# ior7f701057 register map
Registers are 8-bit, access not given, no defined reset value unless marked. A register's access mark holds for its fields unless they carry their own. Addresses are absolute; registers are grouped by the start of their names; [hi:lo] are bit positions; {n}, {i} and the like mark numbered series; 'fields as' and 'values as' point back to an identical list.

## SFR (part 3 of 3)
0xFFFF9002 ICCSIH3ICL_1
0xFFFF9003 ICTAUD0I2H
  [7] CTCSIH3IC_1 ro, [7] CTTAUD0I2 ro, [4] RFCSIH3IC_1, [4] RFTAUD0I2
0xFFFF9003 ICCSIH3ICH_1
0xFFFF9004 ICTAUD0I4 16-bit
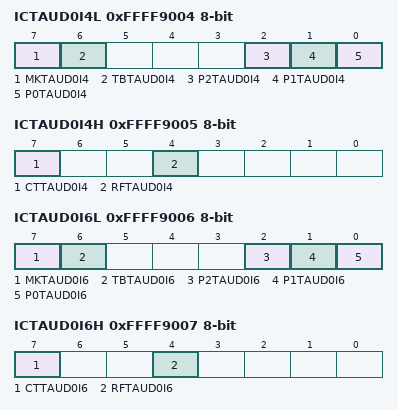
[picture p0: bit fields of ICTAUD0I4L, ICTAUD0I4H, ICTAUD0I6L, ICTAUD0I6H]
0xFFFF9004 ICTAUD0I4L
  [7] MKTAUD0I4, [6] TBTAUD0I4, [2] P2TAUD0I4, [1] P1TAUD0I4, [0] P0TAUD0I4
0xFFFF9005 ICTAUD0I4H
  [7] CTTAUD0I4 ro, [4] RFTAUD0I4
0xFFFF9006 ICTAUD0I6 16-bit
0xFFFF9006 ICTAUD0I6L
  [7] MKTAUD0I6, [6] TBTAUD0I6, [2] P2TAUD0I6, [1] P1TAUD0I6, [0] P0TAUD0I6
0xFFFF9007 ICTAUD0I6H
  [7] CTTAUD0I6 ro, [4] RFTAUD0I6
0xFFFF9008 ICTAUD0I8 16-bit
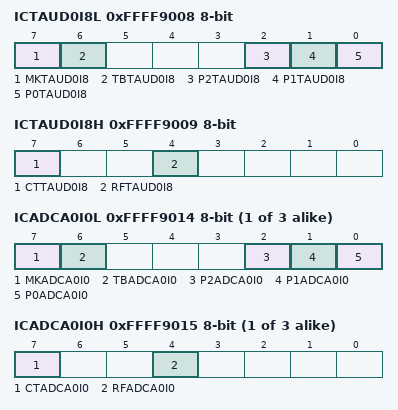
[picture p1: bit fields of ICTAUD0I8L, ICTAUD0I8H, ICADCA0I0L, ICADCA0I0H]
0xFFFF9008 ICTAUD0I8L
  [7] MKTAUD0I8, [6] TBTAUD0I8, [2] P2TAUD0I8, [1] P1TAUD0I8, [0] P0TAUD0I8
0xFFFF9009 ICTAUD0I8H
  [7] CTTAUD0I8 ro, [4] RFTAUD0I8
0xFFFF900A ICTAUD0I10 16-bit
0xFFFF900A ICTAUD0I10L
  [7] MKCSIH3IR_1, [7] MKTAUD0I10, [6] TBCSIH3IR_1, [6] TBTAUD0I10, [2] P2CSIH3IR_1, [2] P2TAUD0I10, [1] P1CSIH3IR_1, [1] P1TAUD0I10, [0] P0CSIH3IR_1, [0] P0TAUD0I10
0xFFFF900A ICCSIH3IR_1 16-bit
0xFFFF900A ICCSIH3IRL_1
0xFFFF900B ICTAUD0I10H
  [7] CTCSIH3IR_1 ro, [7] CTTAUD0I10 ro, [4] RFCSIH3IR_1, [4] RFTAUD0I10
0xFFFF900B ICCSIH3IRH_1
0xFFFF900C ICTAUD0I12 16-bit
0xFFFF900C ICTAUD0I12L
  [7] MKCSIH3IRE_1, [7] MKTAUD0I12, [6] TBCSIH3IRE_1, [6] TBTAUD0I12, [2] P2CSIH3IRE_1, [2] P2TAUD0I12, [1] P1CSIH3IRE_1, [1] P1TAUD0I12, [0] P0CSIH3IRE_1, [0] P0TAUD0I12
0xFFFF900C ICCSIH3IRE_1 16-bit
0xFFFF900C ICCSIH3IREL_1
0xFFFF900D ICTAUD0I12H
  [7] CTCSIH3IRE_1 ro, [7] CTTAUD0I12 ro, [4] RFCSIH3IRE_1, [4] RFTAUD0I12
0xFFFF900D ICCSIH3IREH_1
0xFFFF900E ICTAUD0I14 16-bit
0xFFFF900E ICTAUD0I14L
  [7] MKCSIH3IJC_1, [7] MKTAUD0I14, [6] TBCSIH3IJC_1, [6] TBTAUD0I14, [2] P2CSIH3IJC_1, [2] P2TAUD0I14, [1] P1CSIH3IJC_1, [1] P1TAUD0I14, [0] P0CSIH3IJC_1, [0] P0TAUD0I14
0xFFFF900E ICCSIH3IJC_1 16-bit
0xFFFF900E ICCSIH3IJCL_1
0xFFFF900F ICTAUD0I14H
  [7] CTCSIH3IJC_1 ro, [7] CTTAUD0I14 ro, [4] RFCSIH3IJC_1, [4] RFTAUD0I14
0xFFFF900F ICCSIH3IJCH_1
0xFFFF9010 ICTAPA0IPEK0 16-bit
0xFFFF9010 ICTAPA0IPEK0L
  [7] MKCSIH1IC_1, [7] MKTAPA0IPEK0, [6] TBCSIH1IC_1, [6] TBTAPA0IPEK0, [2] P2CSIH1IC_1, [2] P2TAPA0IPEK0, [1] P1CSIH1IC_1, [1] P1TAPA0IPEK0, [0] P0CSIH1IC_1, [0] P0TAPA0IPEK0
0xFFFF9010 ICCSIH1IC_1 16-bit
0xFFFF9010 ICCSIH1ICL_1
0xFFFF9011 ICTAPA0IPEK0H
  [7] CTCSIH1IC_1 ro, [7] CTTAPA0IPEK0 ro, [4] RFCSIH1IC_1, [4] RFTAPA0IPEK0
0xFFFF9011 ICCSIH1ICH_1
0xFFFF9012 ICTAPA0IVLY0 16-bit
0xFFFF9012 ICTAPA0IVLY0L
  [7] MKCSIH1IR_1, [7] MKTAPA0IVLY0, [6] TBCSIH1IR_1, [6] TBTAPA0IVLY0, [2] P2CSIH1IR_1, [2] P2TAPA0IVLY0, [1] P1CSIH1IR_1, [1] P1TAPA0IVLY0, [0] P0CSIH1IR_1, [0] P0TAPA0IVLY0
0xFFFF9012 ICCSIH1IR_1 16-bit
0xFFFF9012 ICCSIH1IRL_1
0xFFFF9013 ICTAPA0IVLY0H
  [7] CTCSIH1IR_1 ro, [7] CTTAPA0IVLY0 ro, [4] RFCSIH1IR_1, [4] RFTAPA0IVLY0
0xFFFF9013 ICCSIH1IRH_1
{0xFFFF9014+2i} ICADCA0I{i} 16-bit (i=0..2)
{0xFFFF9014+2i} ICADCA0I{i}L (i=0..2)
  [7] MKADCA0I{i}, [6] TBADCA0I{i}, [2] P2ADCA0I{i}, [1] P1ADCA0I{i}, [0] P0ADCA0I{i}
{0xFFFF9015+2i} ICADCA0I{i}H (i=0..2)
  [7] CTADCA0I{i} ro, [4] RFADCA0I{i}
0xFFFF901A ICDCUTDI 16-bit
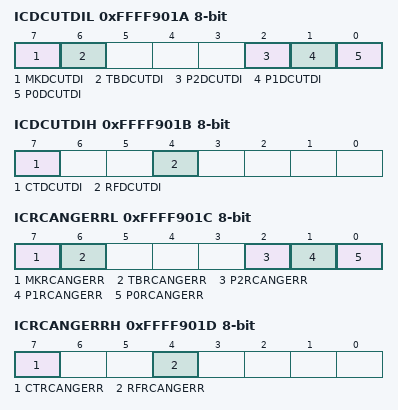
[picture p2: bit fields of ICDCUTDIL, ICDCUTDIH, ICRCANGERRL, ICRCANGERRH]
0xFFFF901A ICDCUTDIL
  [7] MKDCUTDI, [6] TBDCUTDI, [2] P2DCUTDI, [1] P1DCUTDI, [0] P0DCUTDI
0xFFFF901B ICDCUTDIH
  [7] CTDCUTDI ro, [4] RFDCUTDI
0xFFFF901C ICRCANGERR 16-bit
0xFFFF901C ICRCANGERRL
  [7] MKRCANGERR, [6] TBRCANGERR, [2] P2RCANGERR, [1] P1RCANGERR, [0] P0RCANGERR
0xFFFF901D ICRCANGERRH
  [7] CTRCANGERR ro, [4] RFRCANGERR
0xFFFF901E ICRCANGRECC 16-bit
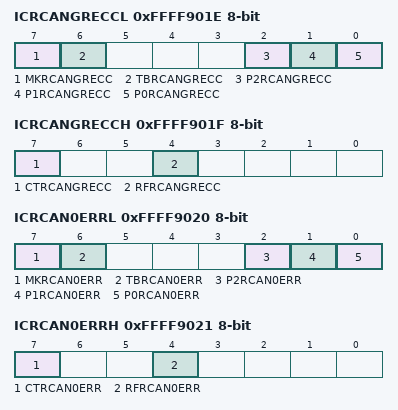
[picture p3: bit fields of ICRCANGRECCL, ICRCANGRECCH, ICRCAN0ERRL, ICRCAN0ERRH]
0xFFFF901E ICRCANGRECCL
  [7] MKRCANGRECC, [6] TBRCANGRECC, [2] P2RCANGRECC, [1] P1RCANGRECC, [0] P0RCANGRECC
0xFFFF901F ICRCANGRECCH
  [7] CTRCANGRECC ro, [4] RFRCANGRECC
0xFFFF9020 ICRCAN0ERR 16-bit
0xFFFF9020 ICRCAN0ERRL
  [7] MKRCAN0ERR, [6] TBRCAN0ERR, [2] P2RCAN0ERR, [1] P1RCAN0ERR, [0] P0RCAN0ERR
0xFFFF9021 ICRCAN0ERRH
  [7] CTRCAN0ERR ro, [4] RFRCAN0ERR
0xFFFF9022 ICRCAN0REC 16-bit
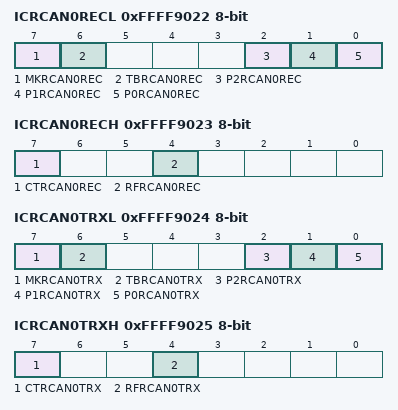
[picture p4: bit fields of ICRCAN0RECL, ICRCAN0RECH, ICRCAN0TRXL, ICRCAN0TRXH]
0xFFFF9022 ICRCAN0RECL
  [7] MKRCAN0REC, [6] TBRCAN0REC, [2] P2RCAN0REC, [1] P1RCAN0REC, [0] P0RCAN0REC
0xFFFF9023 ICRCAN0RECH
  [7] CTRCAN0REC ro, [4] RFRCAN0REC
0xFFFF9024 ICRCAN0TRX 16-bit
0xFFFF9024 ICRCAN0TRXL
  [7] MKRCAN0TRX, [6] TBRCAN0TRX, [2] P2RCAN0TRX, [1] P1RCAN0TRX, [0] P0RCAN0TRX
0xFFFF9025 ICRCAN0TRXH
  [7] CTRCAN0TRX ro, [4] RFRCAN0TRX
0xFFFF9026 ICCSIG0IC 16-bit
0xFFFF9026 ICCSIG0ICL
0xFFFF9026 ICCSIH1IRE_1 16-bit
0xFFFF9026 ICCSIH1IREL_1
  [7] MKCSIG0IC, [7] MKCSIH1IRE_1, [6] TBCSIG0IC, [6] TBCSIH1IRE_1, [2] P2CSIG0IC, [2] P2CSIH1IRE_1, [1] P1CSIG0IC, [1] P1CSIH1IRE_1, [0] P0CSIG0IC, [0] P0CSIH1IRE_1
0xFFFF9027 ICCSIG0ICH
0xFFFF9027 ICCSIH1IREH_1
  [7] CTCSIG0IC ro, [7] CTCSIH1IRE_1 ro, [4] RFCSIG0IC, [4] RFCSIH1IRE_1
0xFFFF9028 ICCSIG0IR 16-bit
0xFFFF9028 ICCSIG0IRL
0xFFFF9028 ICCSIH1IJC_1 16-bit
0xFFFF9028 ICCSIH1IJCL_1
  [7] MKCSIG0IR, [7] MKCSIH1IJC_1, [6] TBCSIG0IR, [6] TBCSIH1IJC_1, [2] P2CSIG0IR, [2] P2CSIH1IJC_1, [1] P1CSIG0IR, [1] P1CSIH1IJC_1, [0] P0CSIG0IR, [0] P0CSIH1IJC_1
0xFFFF9029 ICCSIG0IRH
0xFFFF9029 ICCSIH1IJCH_1
  [7] CTCSIG0IR ro, [7] CTCSIH1IJC_1 ro, [4] RFCSIG0IR, [4] RFCSIH1IJC_1
0xFFFF902A ICCSIH0IC 16-bit
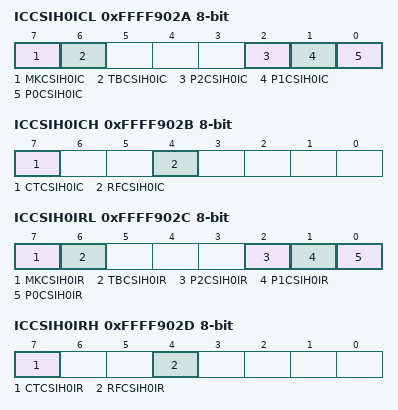
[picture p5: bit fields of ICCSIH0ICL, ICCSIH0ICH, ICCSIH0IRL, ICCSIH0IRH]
0xFFFF902A ICCSIH0ICL
  [7] MKCSIH0IC, [6] TBCSIH0IC, [2] P2CSIH0IC, [1] P1CSIH0IC, [0] P0CSIH0IC
0xFFFF902B ICCSIH0ICH
  [7] CTCSIH0IC ro, [4] RFCSIH0IC
0xFFFF902C ICCSIH0IR 16-bit
0xFFFF902C ICCSIH0IRL
  [7] MKCSIH0IR, [6] TBCSIH0IR, [2] P2CSIH0IR, [1] P1CSIH0IR, [0] P0CSIH0IR
0xFFFF902D ICCSIH0IRH
  [7] CTCSIH0IR ro, [4] RFCSIH0IR
0xFFFF902E ICCSIH0IRE 16-bit
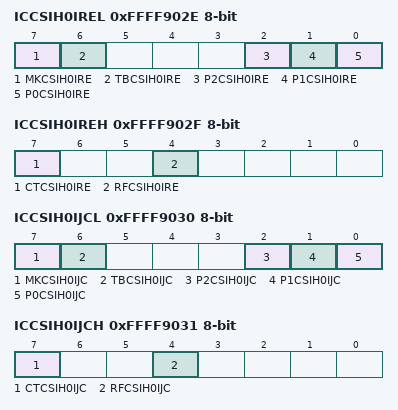
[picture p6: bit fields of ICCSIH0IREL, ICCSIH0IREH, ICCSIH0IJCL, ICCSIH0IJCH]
0xFFFF902E ICCSIH0IREL
  [7] MKCSIH0IRE, [6] TBCSIH0IRE, [2] P2CSIH0IRE, [1] P1CSIH0IRE, [0] P0CSIH0IRE
0xFFFF902F ICCSIH0IREH
  [7] CTCSIH0IRE ro, [4] RFCSIH0IRE
0xFFFF9030 ICCSIH0IJC 16-bit
0xFFFF9030 ICCSIH0IJCL
  [7] MKCSIH0IJC, [6] TBCSIH0IJC, [2] P2CSIH0IJC, [1] P1CSIH0IJC, [0] P0CSIH0IJC
0xFFFF9031 ICCSIH0IJCH
  [7] CTCSIH0IJC ro, [4] RFCSIH0IJC
0xFFFF9032 ICRLIN30 16-bit
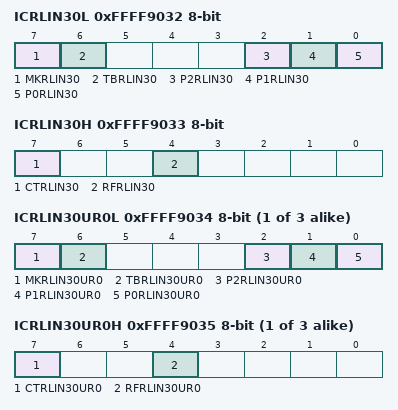
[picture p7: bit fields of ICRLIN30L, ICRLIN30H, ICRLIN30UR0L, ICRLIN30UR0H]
0xFFFF9032 ICRLIN30L
  [7] MKRLIN30, [6] TBRLIN30, [2] P2RLIN30, [1] P1RLIN30, [0] P0RLIN30
0xFFFF9033 ICRLIN30H
  [7] CTRLIN30 ro, [4] RFRLIN30
{0xFFFF9034+2i} ICRLIN30UR{i} 16-bit (i=0..2)
{0xFFFF9034+2i} ICRLIN30UR{i}L (i=0..2)
  [7] MKRLIN30UR{i}, [6] TBRLIN30UR{i}, [2] P2RLIN30UR{i}, [1] P1RLIN30UR{i}, [0] P0RLIN30UR{i}
{0xFFFF9035+2i} ICRLIN30UR{i}H (i=0..2)
  [7] CTRLIN30UR{i} ro, [4] RFRLIN30UR{i}
{0xFFFF903A+2i} ICP{i} 16-bit (i=0..2)
0xFFFF903A ICP0L
  [7] MKCSIH2IR_1, [7] MKP0, [6] TBCSIH2IR_1, [6] TBP0, [2] P2CSIH2IR_1, [2] P2P0, [1] P1CSIH2IR_1, [1] P1P0, [0] P0CSIH2IR_1, [0] P0P0
0xFFFF903A ICCSIH2IR_1 16-bit
0xFFFF903A ICCSIH2IRL_1
0xFFFF903B ICP0H
  [7] CTCSIH2IR_1 ro, [7] CTP0 ro, [4] RFCSIH2IR_1, [4] RFP0
0xFFFF903B ICCSIH2IRH_1
0xFFFF903C ICP1L
  [7] MKCSIH2IRE_1, [7] MKP1, [6] TBCSIH2IRE_1, [6] TBP1, [2] P2CSIH2IRE_1, [2] P2P1, [1] P1CSIH2IRE_1, [1] P1P1, [0] P0CSIH2IRE_1, [0] P0P1
0xFFFF903C ICCSIH2IRE_1 16-bit
0xFFFF903C ICCSIH2IREL_1
0xFFFF903D ICP1H
  [7] CTCSIH2IRE_1 ro, [7] CTP1 ro, [4] RFCSIH2IRE_1, [4] RFP1
0xFFFF903D ICCSIH2IREH_1
0xFFFF903E ICP2L
  [7] MKCSIH2IJC_1, [7] MKP2, [6] TBCSIH2IJC_1, [6] TBP2, [2] P2CSIH2IJC_1, [2] P2P2, [1] P1CSIH2IJC_1, [1] P1P2, [0] P0CSIH2IJC_1, [0] P0P2
0xFFFF903E ICCSIH2IJC_1 16-bit
0xFFFF903E ICCSIH2IJCL_1
0xFFFF903F ICP2H
  [7] CTCSIH2IJC_1 ro, [7] CTP2 ro, [4] RFCSIH2IJC_1, [4] RFP2
0xFFFF903F ICCSIH2IJCH_1
0xFFFF9078 FNC 16-bit ro
0xFFFF9079 FNCH ro
  [4] FNRF
0xFFFF907A FIC 16-bit ro
0xFFFF907B FICH ro
  [4] FIRF
0xFFFF90F0 IMR0 32-bit
0xFFFF90F0 IMR0L 16-bit
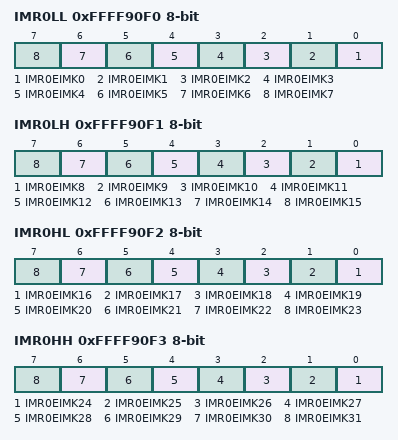
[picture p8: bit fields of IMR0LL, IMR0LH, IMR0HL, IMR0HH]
0xFFFF90F0 IMR0LL
  [n] IMR0EIMK{n} (n=0..7)
0xFFFF90F1 IMR0LH
  [n-8] IMR0EIMK{n} (n=8..15)
0xFFFF90F2 IMR0H 16-bit
0xFFFF90F2 IMR0HL
  [n-16] IMR0EIMK{n} (n=16..23)
0xFFFF90F3 IMR0HH
  [n-24] IMR0EIMK{n} (n=24..31)
0xFFFFA040 ICWDTA0 16-bit
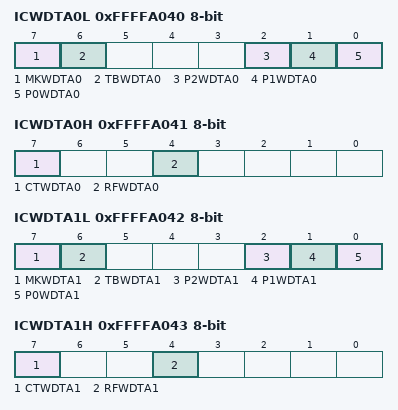
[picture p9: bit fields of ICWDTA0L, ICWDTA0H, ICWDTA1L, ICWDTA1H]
0xFFFFA040 ICWDTA0L
  [7] MKWDTA0, [6] TBWDTA0, [2] P2WDTA0, [1] P1WDTA0, [0] P0WDTA0
0xFFFFA041 ICWDTA0H
  [7] CTWDTA0 ro, [4] RFWDTA0
0xFFFFA042 ICWDTA1 16-bit
0xFFFFA042 ICWDTA1L
  [7] MKWDTA1, [6] TBWDTA1, [2] P2WDTA1, [1] P1WDTA1, [0] P0WDTA1
0xFFFFA043 ICWDTA1H
  [7] CTWDTA1 ro, [4] RFWDTA1
{0xFFFFA03E+2i} ICP{i} 16-bit (i=3..5)
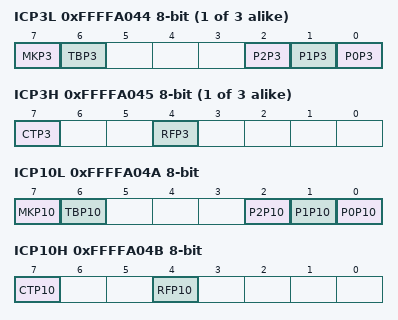
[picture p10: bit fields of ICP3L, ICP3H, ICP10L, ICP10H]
{0xFFFFA03E+2i} ICP{i}L (i=3..5)
  [7] MKP{i}, [6] TBP{i}, [2] P2P{i}, [1] P1P{i}, [0] P0P{i}
{0xFFFFA03F+2i} ICP{i}H (i=3..5)
  [7] CTP{i} ro, [4] RFP{i}
0xFFFFA04A ICP10 16-bit
0xFFFFA04A ICP10L
  [7] MKP10, [6] TBP10, [2] P2P10, [1] P1P10, [0] P0P10
0xFFFFA04B ICP10H
  [7] CTP10 ro, [4] RFP10
0xFFFFA04C ICP11 16-bit
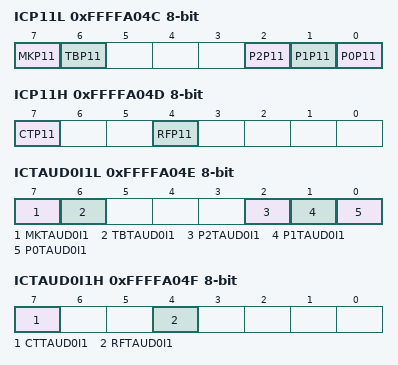
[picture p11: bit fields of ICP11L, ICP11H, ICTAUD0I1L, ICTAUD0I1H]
0xFFFFA04C ICP11L
  [7] MKP11, [6] TBP11, [2] P2P11, [1] P1P11, [0] P0P11
0xFFFFA04D ICP11H
  [7] CTP11 ro, [4] RFP11
0xFFFFA04E ICTAUD0I1 16-bit
0xFFFFA04E ICTAUD0I1L
  [7] MKTAUD0I1, [6] TBTAUD0I1, [2] P2TAUD0I1, [1] P1TAUD0I1, [0] P0TAUD0I1
0xFFFFA04F ICTAUD0I1H
  [7] CTTAUD0I1 ro, [4] RFTAUD0I1
0xFFFFA050 ICTAUD0I3 16-bit
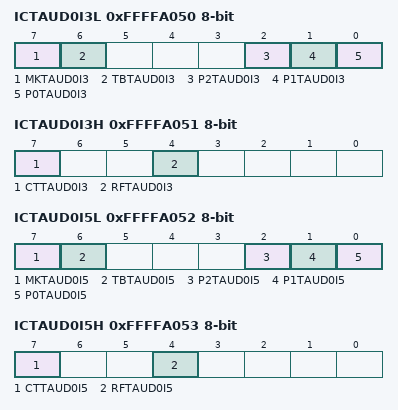
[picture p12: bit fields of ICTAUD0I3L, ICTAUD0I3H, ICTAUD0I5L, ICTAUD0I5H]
0xFFFFA050 ICTAUD0I3L
  [7] MKTAUD0I3, [6] TBTAUD0I3, [2] P2TAUD0I3, [1] P1TAUD0I3, [0] P0TAUD0I3
0xFFFFA051 ICTAUD0I3H
  [7] CTTAUD0I3 ro, [4] RFTAUD0I3
0xFFFFA052 ICTAUD0I5 16-bit
0xFFFFA052 ICTAUD0I5L
  [7] MKTAUD0I5, [6] TBTAUD0I5, [2] P2TAUD0I5, [1] P1TAUD0I5, [0] P0TAUD0I5
0xFFFFA053 ICTAUD0I5H
  [7] CTTAUD0I5 ro, [4] RFTAUD0I5
0xFFFFA054 ICTAUD0I7 16-bit
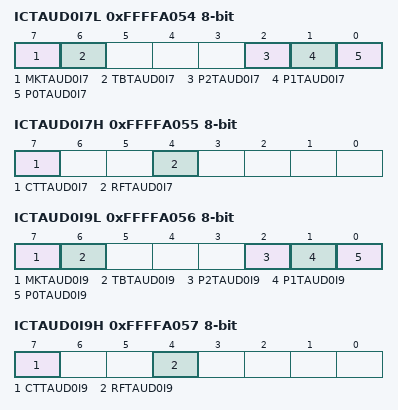
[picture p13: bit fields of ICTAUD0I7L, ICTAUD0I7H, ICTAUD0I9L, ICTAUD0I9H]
0xFFFFA054 ICTAUD0I7L
  [7] MKTAUD0I7, [6] TBTAUD0I7, [2] P2TAUD0I7, [1] P1TAUD0I7, [0] P0TAUD0I7
0xFFFFA055 ICTAUD0I7H
  [7] CTTAUD0I7 ro, [4] RFTAUD0I7
0xFFFFA056 ICTAUD0I9 16-bit
0xFFFFA056 ICTAUD0I9L
  [7] MKTAUD0I9, [6] TBTAUD0I9, [2] P2TAUD0I9, [1] P1TAUD0I9, [0] P0TAUD0I9
0xFFFFA057 ICTAUD0I9H
  [7] CTTAUD0I9 ro, [4] RFTAUD0I9
0xFFFFA058 ICTAUD0I11 16-bit
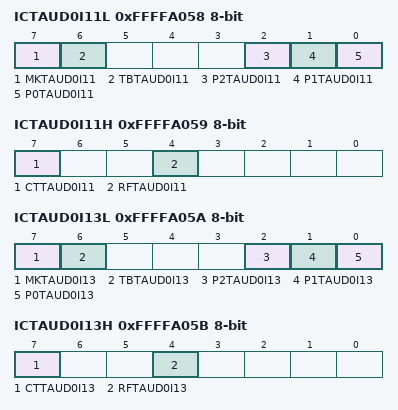
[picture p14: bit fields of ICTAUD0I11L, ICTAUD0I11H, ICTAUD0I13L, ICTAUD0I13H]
0xFFFFA058 ICTAUD0I11L
  [7] MKTAUD0I11, [6] TBTAUD0I11, [2] P2TAUD0I11, [1] P1TAUD0I11, [0] P0TAUD0I11
0xFFFFA059 ICTAUD0I11H
  [7] CTTAUD0I11 ro, [4] RFTAUD0I11
0xFFFFA05A ICTAUD0I13 16-bit
0xFFFFA05A ICTAUD0I13L
  [7] MKTAUD0I13, [6] TBTAUD0I13, [2] P2TAUD0I13, [1] P1TAUD0I13, [0] P0TAUD0I13
0xFFFFA05B ICTAUD0I13H
  [7] CTTAUD0I13 ro, [4] RFTAUD0I13
0xFFFFA05C ICTAUD0I15 16-bit
0xFFFFA05C ICTAUD0I15L
  [7] MKTAUD0I15, [6] TBTAUD0I15, [2] P2TAUD0I15, [1] P1TAUD0I15, [0] P0TAUD0I15
0xFFFFA05D ICTAUD0I15H
  [7] CTTAUD0I15 ro, [4] RFTAUD0I15
0xFFFFA05E ICADCA0ERR 16-bit
0xFFFFA05E ICADCA0ERRL
  [7] MKADCA0ERR, [6] TBADCA0ERR, [2] P2ADCA0ERR, [1] P1ADCA0ERR, [0] P0ADCA0ERR
0xFFFFA05F ICADCA0ERRH
  [7] CTADCA0ERR ro, [4] RFADCA0ERR
0xFFFFA062 ICCSIG0IRE 16-bit
0xFFFFA062 ICCSIG0IREL
  [7] MKCSIG0IRE, [6] TBCSIG0IRE, [2] P2CSIG0IRE, [1] P1CSIG0IRE, [0] P0CSIG0IRE
0xFFFFA063 ICCSIG0IREH
  [7] CTCSIG0IRE ro, [4] RFCSIG0IRE
0xFFFFA064 ICRLIN20 16-bit
0xFFFFA064 ICRLIN20L
  [7] MKRLIN20, [6] TBRLIN20, [2] P2RLIN20, [1] P1RLIN20, [0] P0RLIN20
0xFFFFA065 ICRLIN20H
  [7] CTRLIN20 ro, [4] RFRLIN20
0xFFFFA066 ICRLIN21 16-bit
0xFFFFA066 ICRLIN21L
  [7] MKRLIN21, [6] TBRLIN21, [2] P2RLIN21, [1] P1RLIN21, [0] P0RLIN21
0xFFFFA067 ICRLIN21H
  [7] CTRLIN21 ro, [4] RFRLIN21
{0xFFFFA068+2i} ICDMA{i} 16-bit (i=0..15)
{0xFFFFA068+2i} ICDMA{i}L (i=0..15)
  [7] MKDMA{i}, [6] TBDMA{i}, [2] P2DMA{i}, [1] P1DMA{i}, [0] P0DMA{i}
{0xFFFFA069+2i} ICDMA{i}H (i=0..15)
  [7] CTDMA{i} ro, [4] RFDMA{i}
0xFFFFA088 ICRIIC0TI 16-bit
0xFFFFA088 ICRIIC0TIL
  [7] MKRIIC0TI, [6] TBRIIC0TI, [2] P2RIIC0TI, [1] P1RIIC0TI, [0] P0RIIC0TI
0xFFFFA089 ICRIIC0TIH
  [7] CTRIIC0TI ro, [4] RFRIIC0TI
0xFFFFA08A ICRIIC0TEI 16-bit
0xFFFFA08A ICRIIC0TEIL
  [7] MKRIIC0TEI, [6] TBRIIC0TEI, [2] P2RIIC0TEI, [1] P1RIIC0TEI, [0] P0RIIC0TEI
0xFFFFA08B ICRIIC0TEIH
  [7] CTRIIC0TEI ro, [4] RFRIIC0TEI
0xFFFFA08C ICRIIC0RI 16-bit
0xFFFFA08C ICRIIC0RIL
  [7] MKRIIC0RI, [6] TBRIIC0RI, [2] P2RIIC0RI, [1] P1RIIC0RI, [0] P0RIIC0RI
0xFFFFA08D ICRIIC0RIH
  [7] CTRIIC0RI ro, [4] RFRIIC0RI
0xFFFFA08E ICRIIC0EE 16-bit
0xFFFFA08E ICRIIC0EEL
  [7] MKRIIC0EE, [6] TBRIIC0EE, [2] P2RIIC0EE, [1] P1RIIC0EE, [0] P0RIIC0EE
0xFFFFA08F ICRIIC0EEH
  [7] CTRIIC0EE ro, [4] RFRIIC0EE
{0xFFFFA090+2i} ICTAUJ0I{i} 16-bit (i=0..3)
{0xFFFFA090+2i} ICTAUJ0I{i}L (i=0..3)
  [7] MKTAUJ0I{i}, [6] TBTAUJ0I{i}, [2] P2TAUJ0I{i}, [1] P1TAUJ0I{i}, [0] P0TAUJ0I{i}
{0xFFFFA091+2i} ICTAUJ0I{i}H (i=0..3)
  [7] CTTAUJ0I{i} ro, [4] RFTAUJ0I{i}
0xFFFFA098 ICOSTM0 16-bit
0xFFFFA098 ICOSTM0L
  [7] MKOSTM0, [6] TBOSTM0, [2] P2OSTM0, [1] P1OSTM0, [0] P0OSTM0
0xFFFFA099 ICOSTM0H
  [7] CTOSTM0 ro, [4] RFOSTM0
0xFFFFA09A ICENCA0IOV 16-bit
{0xFFFFA092+2i} ICPWGA{i} 16-bit (i=4..7)
0xFFFFA09A ICENCA0IOVL
0xFFFFA09A ICPWGA4L
  [7] MKENCA0IOV, [7] MKPWGA4, [6] TBENCA0IOV, [6] TBPWGA4, [2] P2ENCA0IOV, [2] P2PWGA4, [1] P1ENCA0IOV, [1] P1PWGA4, [0] P0ENCA0IOV, [0] P0PWGA4
0xFFFFA09B ICENCA0IOVH
0xFFFFA09B ICPWGA4H
  [7] CTENCA0IOV ro, [7] CTPWGA4 ro, [4] RFENCA0IOV, [4] RFPWGA4
0xFFFFA09C ICENCA0IUD 16-bit
0xFFFFA09C ICENCA0IUDL
0xFFFFA09C ICPWGA5L
  [7] MKENCA0IUD, [7] MKPWGA5, [6] TBENCA0IUD, [6] TBPWGA5, [2] P2ENCA0IUD, [2] P2PWGA5, [1] P1ENCA0IUD, [1] P1PWGA5, [0] P0ENCA0IUD, [0] P0PWGA5
0xFFFFA09D ICENCA0IUDH
0xFFFFA09D ICPWGA5H
  [7] CTENCA0IUD ro, [7] CTPWGA5 ro, [4] RFENCA0IUD, [4] RFPWGA5
0xFFFFA09E ICENCA0I0 16-bit
0xFFFFA09E ICENCA0I0L
0xFFFFA09E ICPWGA6L
  [7] MKENCA0I0, [7] MKPWGA6, [6] TBENCA0I0, [6] TBPWGA6, [2] P2ENCA0I0, [2] P2PWGA6, [1] P1ENCA0I0, [1] P1PWGA6, [0] P0ENCA0I0, [0] P0PWGA6
0xFFFFA09F ICENCA0I0H
0xFFFFA09F ICPWGA6H
  [7] CTENCA0I0 ro, [7] CTPWGA6 ro, [4] RFENCA0I0, [4] RFPWGA6
0xFFFFA0A0 ICENCA0I1 16-bit
0xFFFFA0A0 ICENCA0I1L
0xFFFFA0A0 ICPWGA7L
  [7] MKENCA0I1, [7] MKPWGA7, [6] TBENCA0I1, [6] TBPWGA7, [2] P2ENCA0I1, [2] P2PWGA7, [1] P1ENCA0I1, [1] P1PWGA7, [0] P0ENCA0I1, [0] P0PWGA7
0xFFFFA0A1 ICENCA0I1H
0xFFFFA0A1 ICPWGA7H
  [7] CTENCA0I1 ro, [7] CTPWGA7 ro, [4] RFENCA0I1, [4] RFPWGA7
0xFFFFA0A2 ICENCA0IEC 16-bit
0xFFFFA0A2 ICENCA0IECL
  [7] MKENCA0IEC, [6] TBENCA0IEC, [2] P2ENCA0IEC, [1] P1ENCA0IEC, [0] P0ENCA0IEC
0xFFFFA0A3 ICENCA0IECH
  [7] CTENCA0IEC ro, [4] RFENCA0IEC
0xFFFFA0A4 ICKR0 16-bit
0xFFFFA0A4 ICKR0L
  [7] MKKR0, [6] TBKR0, [2] P2KR0, [1] P1KR0, [0] P0KR0
0xFFFFA0A5 ICKR0H
  [7] CTKR0 ro, [4] RFKR0
0xFFFFA0A6 ICQFULL 16-bit
0xFFFFA0A6 ICQFULLL
  [7] MKQFULL, [6] TBQFULL, [2] P2QFULL, [1] P1QFULL, [0] P0QFULL
0xFFFFA0A7 ICQFULLH
  [7] CTQFULL ro, [4] RFQFULL
{0xFFFFA0A8+2i} ICPWGA{i} 16-bit (i=0..3)
{0xFFFFA0A8+2i} ICPWGA{i}L (i=0..3)
  [7] MKPWGA{i}, [6] TBPWGA{i}, [2] P2PWGA{i}, [1] P1PWGA{i}, [0] P0PWGA{i}
{0xFFFFA0A9+2i} ICPWGA{i}H (i=0..3)
  [7] CTPWGA{i} ro, [4] RFPWGA{i}
{0xFFFFA0A0+2i} ICPWGA{i} 16-bit (i=8..15)
{0xFFFFA0A0+2i} ICPWGA{i}L (i=8..15)
  fields as ICPWGA0L
{0xFFFFA0A1+2i} ICPWGA{i}H (i=8..15)
  [7] CTPWGA{i} ro, [4] RFPWGA{i}
0xFFFFA0CC ICFLERR 16-bit
0xFFFFA0CC ICFLERRL
  [7] MKFLERR, [6] TBFLERR, [2] P2FLERR, [1] P1FLERR, [0] P0FLERR
0xFFFFA0CD ICFLERRH
  [7] CTFLERR ro, [4] RFFLERR
0xFFFFA0CE ICFLENDNM 16-bit
0xFFFFA0CE ICFLENDNML
  [7] MKFLENDNM, [6] TBFLENDNM, [2] P2FLENDNM, [1] P1FLENDNM, [0] P0FLENDNM
0xFFFFA0CF ICFLENDNMH
  [7] CTFLENDNM ro, [4] RFFLENDNM
0xFFFFA0D0 ICCWEND 16-bit
0xFFFFA0D0 ICCWENDL
  [7] MKCWEND, [6] TBCWEND, [2] P2CWEND, [1] P1CWEND, [0] P0CWEND
0xFFFFA0D1 ICCWENDH
  [7] CTCWEND ro, [4] RFCWEND
0xFFFFA0D2 ICRCAN1ERR 16-bit
0xFFFFA0D2 ICRCAN1ERRL
  [7] MKRCAN1ERR, [6] TBRCAN1ERR, [2] P2RCAN1ERR, [1] P1RCAN1ERR, [0] P0RCAN1ERR
0xFFFFA0D3 ICRCAN1ERRH
  [7] CTRCAN1ERR ro, [4] RFRCAN1ERR
0xFFFFA0D4 ICRCAN1REC 16-bit
0xFFFFA0D4 ICRCAN1RECL
  [7] MKRCAN1REC, [6] TBRCAN1REC, [2] P2RCAN1REC, [1] P1RCAN1REC, [0] P0RCAN1REC
0xFFFFA0D5 ICRCAN1RECH
  [7] CTRCAN1REC ro, [4] RFRCAN1REC
0xFFFFA0D6 ICRCAN1TRX 16-bit
0xFFFFA0D6 ICRCAN1TRXL
  [7] MKRCAN1TRX, [6] TBRCAN1TRX, [2] P2RCAN1TRX, [1] P1RCAN1TRX, [0] P0RCAN1TRX
0xFFFFA0D7 ICRCAN1TRXH
  [7] CTRCAN1TRX ro, [4] RFRCAN1TRX
0xFFFFA0D8 ICCSIH1IC 16-bit
0xFFFFA0D8 ICCSIH1ICL
0xFFFFA0D8 ICTAPA0IPEK0_2 16-bit
0xFFFFA0D8 ICTAPA0IPEK0L_2
  [7] MKCSIH1IC, [7] MKTAPA0IPEK0_2, [6] TBCSIH1IC, [6] TBTAPA0IPEK0_2, [2] P2CSIH1IC, [2] P2TAPA0IPEK0_2, [1] P1CSIH1IC, [1] P1TAPA0IPEK0_2, [0] P0CSIH1IC, [0] P0TAPA0IPEK0_2
0xFFFFA0D9 ICCSIH1ICH
0xFFFFA0D9 ICTAPA0IPEK0H_2
  [7] CTCSIH1IC ro, [7] CTTAPA0IPEK0_2 ro, [4] RFCSIH1IC, [4] RFTAPA0IPEK0_2
0xFFFFA0DA ICCSIH1IR 16-bit
0xFFFFA0DA ICCSIH1IRL
0xFFFFA0DA ICTAPA0IVLY0_2 16-bit
0xFFFFA0DA ICTAPA0IVLY0L_2
  [7] MKCSIH1IR, [7] MKTAPA0IVLY0_2, [6] TBCSIH1IR, [6] TBTAPA0IVLY0_2, [2] P2CSIH1IR, [2] P2TAPA0IVLY0_2, [1] P1CSIH1IR, [1] P1TAPA0IVLY0_2, [0] P0CSIH1IR, [0] P0TAPA0IVLY0_2
0xFFFFA0DB ICCSIH1IRH
0xFFFFA0DB ICTAPA0IVLY0H_2
  [7] CTCSIH1IR ro, [7] CTTAPA0IVLY0_2 ro, [4] RFCSIH1IR, [4] RFTAPA0IVLY0_2
0xFFFFA0DC ICCSIH1IRE 16-bit
0xFFFFA0DC ICCSIH1IREL
  [7] MKCSIG0IC_2, [7] MKCSIH1IRE, [6] TBCSIG0IC_2, [6] TBCSIH1IRE, [2] P2CSIG0IC_2, [2] P2CSIH1IRE, [1] P1CSIG0IC_2, [1] P1CSIH1IRE, [0] P0CSIG0IC_2, [0] P0CSIH1IRE
0xFFFFA0DC ICCSIG0IC_2 16-bit
0xFFFFA0DC ICCSIG0ICL_2
0xFFFFA0DD ICCSIH1IREH
  [7] CTCSIG0IC_2 ro, [7] CTCSIH1IRE ro, [4] RFCSIG0IC_2, [4] RFCSIH1IRE
0xFFFFA0DD ICCSIG0ICH_2
0xFFFFA0DE ICCSIH1IJC 16-bit
0xFFFFA0DE ICCSIH1IJCL
  [7] MKCSIG0IR_2, [7] MKCSIH1IJC, [6] TBCSIG0IR_2, [6] TBCSIH1IJC, [2] P2CSIG0IR_2, [2] P2CSIH1IJC, [1] P1CSIG0IR_2, [1] P1CSIH1IJC, [0] P0CSIG0IR_2, [0] P0CSIH1IJC
0xFFFFA0DE ICCSIG0IR_2 16-bit
0xFFFFA0DE ICCSIG0IRL_2
0xFFFFA0DF ICCSIH1IJCH
  [7] CTCSIG0IR_2 ro, [7] CTCSIH1IJC ro, [4] RFCSIG0IR_2, [4] RFCSIH1IJC
0xFFFFA0DF ICCSIG0IRH_2
0xFFFFA0E0 ICRLIN31 16-bit
0xFFFFA0E0 ICRLIN31L
  [7] MKRLIN31, [6] TBRLIN31, [2] P2RLIN31, [1] P1RLIN31, [0] P0RLIN31
0xFFFFA0E1 ICRLIN31H
  [7] CTRLIN31 ro, [4] RFRLIN31
{0xFFFFA0E2+2i} ICRLIN31UR{i} 16-bit (i=0..2)
{0xFFFFA0E2+2i} ICRLIN31UR{i}L (i=0..2)
  [7] MKRLIN31UR{i}, [6] TBRLIN31UR{i}, [2] P2RLIN31UR{i}, [1] P1RLIN31UR{i}, [0] P0RLIN31UR{i}
{0xFFFFA0E3+2i} ICRLIN31UR{i}H (i=0..2)
  [7] CTRLIN31UR{i} ro, [4] RFRLIN31UR{i}
{0xFFFFA0C0+2i} ICPWGA{i} 16-bit (i=20..23)
{0xFFFFA0C0+2i} ICPWGA{i}L (i=20..23)
  fields as ICPWGA0L
{0xFFFFA0C1+2i} ICPWGA{i}H (i=20..23)
  [7] CTPWGA{i} ro, [4] RFPWGA{i}
{0xFFFFA0E4+2i} ICP{i} 16-bit (i=6..8)
{0xFFFFA0E4+2i} ICP{i}L (i=6..8)
  [7] MKP{i}, [6] TBP{i}, [2] P2P{i}, [1] P1P{i}, [0] P0P{i}
{0xFFFFA0E5+2i} ICP{i}H (i=6..8)
  [7] CTP{i} ro, [4] RFP{i}
0xFFFFA0F6 ICP12 16-bit
0xFFFFA0F6 ICP12L
  [7] MKP12, [6] TBP12, [2] P2P12, [1] P1P12, [0] P0P12
0xFFFFA0F7 ICP12H
  [7] CTP12 ro, [4] RFP12
0xFFFFA0F8 ICCSIH2IC 16-bit
0xFFFFA0F8 ICCSIH2ICL
0xFFFFA0F8 ICTAUD0I0_2 16-bit
0xFFFFA0F8 ICTAUD0I0L_2
  [7] MKCSIH2IC, [7] MKTAUD0I0_2, [6] TBCSIH2IC, [6] TBTAUD0I0_2, [2] P2CSIH2IC, [2] P2TAUD0I0_2, [1] P1CSIH2IC, [1] P1TAUD0I0_2, [0] P0CSIH2IC, [0] P0TAUD0I0_2
0xFFFFA0F9 ICCSIH2ICH
0xFFFFA0F9 ICTAUD0I0H_2
  [7] CTCSIH2IC ro, [7] CTTAUD0I0_2 ro, [4] RFCSIH2IC, [4] RFTAUD0I0_2
0xFFFFA0FA ICCSIH2IR 16-bit
0xFFFFA0FA ICCSIH2IRL
{0xFFFFA0FA+2i} ICP{i}_2 16-bit (i=0..2)
0xFFFFA0FA ICP0L_2
  [7] MKCSIH2IR, [7] MKP0_2, [6] TBCSIH2IR, [6] TBP0_2, [2] P2CSIH2IR, [2] P2P0_2, [1] P1CSIH2IR, [1] P1P0_2, [0] P0CSIH2IR, [0] P0P0_2
0xFFFFA0FB ICCSIH2IRH
0xFFFFA0FB ICP0H_2
  [7] CTCSIH2IR ro, [7] CTP0_2 ro, [4] RFCSIH2IR, [4] RFP0_2
0xFFFFA0FC ICCSIH2IRE 16-bit
0xFFFFA0FC ICCSIH2IREL
0xFFFFA0FC ICP1L_2
  [7] MKCSIH2IRE, [7] MKP1_2, [6] TBCSIH2IRE, [6] TBP1_2, [2] P2CSIH2IRE, [2] P2P1_2, [1] P1CSIH2IRE, [1] P1P1_2, [0] P0CSIH2IRE, [0] P0P1_2
0xFFFFA0FD ICCSIH2IREH
0xFFFFA0FD ICP1H_2
  [7] CTCSIH2IRE ro, [7] CTP1_2 ro, [4] RFCSIH2IRE, [4] RFP1_2
0xFFFFA0FE ICCSIH2IJC 16-bit
0xFFFFA0FE ICCSIH2IJCL
0xFFFFA0FE ICP2L_2
  [7] MKCSIH2IJC, [7] MKP2_2, [6] TBCSIH2IJC, [6] TBP2_2, [2] P2CSIH2IJC, [2] P2P2_2, [1] P1CSIH2IJC, [1] P1P2_2, [0] P0CSIH2IJC, [0] P0P2_2
0xFFFFA0FF ICCSIH2IJCH
0xFFFFA0FF ICP2H_2
  [7] CTCSIH2IJC ro, [7] CTP2_2 ro, [4] RFCSIH2IJC, [4] RFP2_2
{0xFFFFA10C+2i} ICTAUB0I{i} 16-bit (i=0..15)
{0xFFFFA10C+2i} ICTAUB0I{i}L (i=0..2)
  [7] MKTAUB0I{i}, [6] TBTAUB0I{i}, [2] P2TAUB0I{i}, [1] P1TAUB0I{i}, [0] P0TAUB0I{i}
{0xFFFFA10D+2i} ICTAUB0I{i}H (i=0..2)
  [7] CTTAUB0I{i} ro, [4] RFTAUB0I{i}
{0xFFFFA0D2+4i} ICPWGA{i} 16-bit (i=16..19)
{0xFFFFA0D2+4i} ICPWGA{i}L (i=16..19)
0xFFFFA112 ICTAUB0I3L
  [7] MKPWGA16, [7] MKTAUB0I3, [6] TBPWGA16, [6] TBTAUB0I3, [2] P2PWGA16, [2] P2TAUB0I3, [1] P1PWGA16, [1] P1TAUB0I3, [0] P0PWGA16, [0] P0TAUB0I3
{0xFFFFA0D3+4i} ICPWGA{i}H (i=16..19)
0xFFFFA113 ICTAUB0I3H
  [7] CTPWGA16 ro, [7] CTTAUB0I3 ro, [4] RFPWGA16, [4] RFTAUB0I3
0xFFFFA114 ICTAUB0I4L
  [7] MKTAUB0I4, [6] TBTAUB0I4, [2] P2TAUB0I4, [1] P1TAUB0I4, [0] P0TAUB0I4
0xFFFFA115 ICTAUB0I4H
  [7] CTTAUB0I4 ro, [4] RFTAUB0I4
0xFFFFA116 ICTAUB0I5L
  [7] MKPWGA17, [7] MKTAUB0I5, [6] TBPWGA17, [6] TBTAUB0I5, [2] P2PWGA17, [2] P2TAUB0I5, [1] P1PWGA17, [1] P1TAUB0I5, [0] P0PWGA17, [0] P0TAUB0I5
0xFFFFA117 ICTAUB0I5H
  [7] CTPWGA17 ro, [7] CTTAUB0I5 ro, [4] RFPWGA17, [4] RFTAUB0I5
0xFFFFA118 ICTAUB0I6L
  [7] MKTAUB0I6, [6] TBTAUB0I6, [2] P2TAUB0I6, [1] P1TAUB0I6, [0] P0TAUB0I6
0xFFFFA119 ICTAUB0I6H
  [7] CTTAUB0I6 ro, [4] RFTAUB0I6
0xFFFFA11A ICTAUB0I7L
  [7] MKPWGA18, [7] MKTAUB0I7, [6] TBPWGA18, [6] TBTAUB0I7, [2] P2PWGA18, [2] P2TAUB0I7, [1] P1PWGA18, [1] P1TAUB0I7, [0] P0PWGA18, [0] P0TAUB0I7
0xFFFFA11B ICTAUB0I7H
  [7] CTPWGA18 ro, [7] CTTAUB0I7 ro, [4] RFPWGA18, [4] RFTAUB0I7
0xFFFFA11C ICTAUB0I8L
  [7] MKTAUB0I8, [6] TBTAUB0I8, [2] P2TAUB0I8, [1] P1TAUB0I8, [0] P0TAUB0I8
0xFFFFA11D ICTAUB0I8H
  [7] CTTAUB0I8 ro, [4] RFTAUB0I8
0xFFFFA11E ICTAUB0I9L
  [7] MKPWGA19, [7] MKTAUB0I9, [6] TBPWGA19, [6] TBTAUB0I9, [2] P2PWGA19, [2] P2TAUB0I9, [1] P1PWGA19, [1] P1TAUB0I9, [0] P0PWGA19, [0] P0TAUB0I9
0xFFFFA11F ICTAUB0I9H
  [7] CTPWGA19 ro, [7] CTTAUB0I9 ro, [4] RFPWGA19, [4] RFTAUB0I9
0xFFFFA120 ICTAUB0I10L
  [7] MKTAUB0I10, [6] TBTAUB0I10, [2] P2TAUB0I10, [1] P1TAUB0I10, [0] P0TAUB0I10
0xFFFFA121 ICTAUB0I10H
  [7] CTTAUB0I10 ro, [4] RFTAUB0I10
0xFFFFA122 ICPWGA26 16-bit
0xFFFFA122 ICPWGA26L
0xFFFFA122 ICTAUB0I11L
  [7] MKPWGA26, [7] MKTAUB0I11, [6] TBPWGA26, [6] TBTAUB0I11, [2] P2PWGA26, [2] P2TAUB0I11, [1] P1PWGA26, [1] P1TAUB0I11, [0] P0PWGA26, [0] P0TAUB0I11
0xFFFFA123 ICPWGA26H
0xFFFFA123 ICTAUB0I11H
  [7] CTPWGA26 ro, [7] CTTAUB0I11 ro, [4] RFPWGA26, [4] RFTAUB0I11
0xFFFFA124 ICTAUB0I12L
  [7] MKTAUB0I12, [6] TBTAUB0I12, [2] P2TAUB0I12, [1] P1TAUB0I12, [0] P0TAUB0I12
0xFFFFA125 ICTAUB0I12H
  [7] CTTAUB0I12 ro, [4] RFTAUB0I12
0xFFFFA126 ICPWGA30 16-bit
0xFFFFA126 ICPWGA30L
0xFFFFA126 ICTAUB0I13L
  [7] MKPWGA30, [7] MKTAUB0I13, [6] TBPWGA30, [6] TBTAUB0I13, [2] P2PWGA30, [2] P2TAUB0I13, [1] P1PWGA30, [1] P1TAUB0I13, [0] P0PWGA30, [0] P0TAUB0I13
0xFFFFA127 ICPWGA30H
0xFFFFA127 ICTAUB0I13H
  [7] CTPWGA30 ro, [7] CTTAUB0I13 ro, [4] RFPWGA30, [4] RFTAUB0I13
0xFFFFA128 ICTAUB0I14L
  [7] MKTAUB0I14, [6] TBTAUB0I14, [2] P2TAUB0I14, [1] P1TAUB0I14, [0] P0TAUB0I14
0xFFFFA129 ICTAUB0I14H
  [7] CTTAUB0I14 ro, [4] RFTAUB0I14
0xFFFFA12A ICPWGA31 16-bit
0xFFFFA12A ICPWGA31L
0xFFFFA12A ICTAUB0I15L
  [7] MKPWGA31, [7] MKTAUB0I15, [6] TBPWGA31, [6] TBTAUB0I15, [2] P2PWGA31, [2] P2TAUB0I15, [1] P1PWGA31, [1] P1TAUB0I15, [0] P0PWGA31, [0] P0TAUB0I15
0xFFFFA12B ICPWGA31H
0xFFFFA12B ICTAUB0I15H
  [7] CTPWGA31 ro, [7] CTTAUB0I15 ro, [4] RFPWGA31, [4] RFTAUB0I15
0xFFFFA12C ICCSIH3IC 16-bit
0xFFFFA12C ICCSIH3ICL
0xFFFFA12C ICTAUD0I2_2 16-bit
0xFFFFA12C ICTAUD0I2L_2
  [7] MKCSIH3IC, [7] MKTAUD0I2_2, [6] TBCSIH3IC, [6] TBTAUD0I2_2, [2] P2CSIH3IC, [2] P2TAUD0I2_2, [1] P1CSIH3IC, [1] P1TAUD0I2_2, [0] P0CSIH3IC, [0] P0TAUD0I2_2
0xFFFFA12D ICCSIH3ICH
0xFFFFA12D ICTAUD0I2H_2
  [7] CTCSIH3IC ro, [7] CTTAUD0I2_2 ro, [4] RFCSIH3IC, [4] RFTAUD0I2_2
0xFFFFA12E ICCSIH3IR 16-bit
0xFFFFA12E ICCSIH3IRL
0xFFFFA12E ICTAUD0I10_2 16-bit
0xFFFFA12E ICTAUD0I10L_2
  [7] MKCSIH3IR, [7] MKTAUD0I10_2, [6] TBCSIH3IR, [6] TBTAUD0I10_2, [2] P2CSIH3IR, [2] P2TAUD0I10_2, [1] P1CSIH3IR, [1] P1TAUD0I10_2, [0] P0CSIH3IR, [0] P0TAUD0I10_2
0xFFFFA12F ICCSIH3IRH
0xFFFFA12F ICTAUD0I10H_2
  [7] CTCSIH3IR ro, [7] CTTAUD0I10_2 ro, [4] RFCSIH3IR, [4] RFTAUD0I10_2
0xFFFFA130 ICCSIH3IRE 16-bit
0xFFFFA130 ICCSIH3IREL
0xFFFFA130 ICTAUD0I12_2 16-bit
0xFFFFA130 ICTAUD0I12L_2
  [7] MKCSIH3IRE, [7] MKTAUD0I12_2, [6] TBCSIH3IRE, [6] TBTAUD0I12_2, [2] P2CSIH3IRE, [2] P2TAUD0I12_2, [1] P1CSIH3IRE, [1] P1TAUD0I12_2, [0] P0CSIH3IRE, [0] P0TAUD0I12_2
0xFFFFA131 ICCSIH3IREH
0xFFFFA131 ICTAUD0I12H_2
  [7] CTCSIH3IRE ro, [7] CTTAUD0I12_2 ro, [4] RFCSIH3IRE, [4] RFTAUD0I12_2
0xFFFFA132 ICCSIH3IJC 16-bit
0xFFFFA132 ICCSIH3IJCL
0xFFFFA132 ICTAUD0I14_2 16-bit
0xFFFFA132 ICTAUD0I14L_2
  [7] MKCSIH3IJC, [7] MKTAUD0I14_2, [6] TBCSIH3IJC, [6] TBTAUD0I14_2, [2] P2CSIH3IJC, [2] P2TAUD0I14_2, [1] P1CSIH3IJC, [1] P1TAUD0I14_2, [0] P0CSIH3IJC, [0] P0TAUD0I14_2
0xFFFFA133 ICCSIH3IJCH
0xFFFFA133 ICTAUD0I14H_2
  [7] CTCSIH3IJC ro, [7] CTTAUD0I14_2 ro, [4] RFCSIH3IJC, [4] RFTAUD0I14_2
0xFFFFA134 ICRLIN22 16-bit
0xFFFFA134 ICRLIN22L
  [7] MKRLIN22, [6] TBRLIN22, [2] P2RLIN22, [1] P1RLIN22, [0] P0RLIN22
0xFFFFA135 ICRLIN22H
  [7] CTRLIN22 ro, [4] RFRLIN22
0xFFFFA136 ICRLIN23 16-bit
0xFFFFA136 ICRLIN23L
  [7] MKRLIN23, [6] TBRLIN23, [2] P2RLIN23, [1] P1RLIN23, [0] P0RLIN23
0xFFFFA137 ICRLIN23H
  [7] CTRLIN23 ro, [4] RFRLIN23
0xFFFFA138 ICRLIN32 16-bit
0xFFFFA138 ICRLIN32L
  [7] MKRLIN32, [6] TBRLIN32, [2] P2RLIN32, [1] P1RLIN32, [0] P0RLIN32
0xFFFFA139 ICRLIN32H
  [7] CTRLIN32 ro, [4] RFRLIN32
{0xFFFFA13A+2i} ICRLIN32UR{i} 16-bit (i=0..2)
{0xFFFFA13A+2i} ICRLIN32UR{i}L (i=0..2)
  [7] MKRLIN32UR{i}, [6] TBRLIN32UR{i}, [2] P2RLIN32UR{i}, [1] P1RLIN32UR{i}, [0] P0RLIN32UR{i}
{0xFFFFA13B+2i} ICRLIN32UR{i}H (i=0..2)
  [7] CTRLIN32UR{i} ro, [4] RFRLIN32UR{i}
{0xFFFFA140+2i} ICTAUJ1I{i} 16-bit (i=0..3)
{0xFFFFA140+2i} ICTAUJ1I{i}L (i=0..3)
  [7] MKTAUJ1I{i}, [6] TBTAUJ1I{i}, [2] P2TAUJ1I{i}, [1] P1TAUJ1I{i}, [0] P0TAUJ1I{i}
{0xFFFFA141+2i} ICTAUJ1I{i}H (i=0..3)
  [7] CTTAUJ1I{i} ro, [4] RFTAUJ1I{i}
0xFFFFA160 ICPWGA24 16-bit
0xFFFFA160 ICPWGA24L
  [7] MKPWGA24, [6] TBPWGA24, [2] P2PWGA24, [1] P1PWGA24, [0] P0PWGA24
0xFFFFA161 ICPWGA24H
  [7] CTPWGA24 ro, [4] RFPWGA24
0xFFFFA162 ICPWGA25 16-bit
0xFFFFA162 ICPWGA25L
  [7] MKPWGA25, [6] TBPWGA25, [2] P2PWGA25, [1] P1PWGA25, [0] P0PWGA25
0xFFFFA163 ICPWGA25H
  [7] CTPWGA25 ro, [4] RFPWGA25
{0xFFFFA12E+2i} ICPWGA{i} 16-bit (i=27..29)
{0xFFFFA12E+2i} ICPWGA{i}L (i=27..29)
  fields as ICPWGA0L
{0xFFFFA12F+2i} ICPWGA{i}H (i=27..29)
  [7] CTPWGA{i} ro, [4] RFPWGA{i}
{0xFFFFA12A+2i} ICPWGA{i} 16-bit (i=32..47)
{0xFFFFA12A+2i} ICPWGA{i}L (i=32..47)
  fields as ICPWGA0L
{0xFFFFA12B+2i} ICPWGA{i}H (i=32..47)
  [7] CTPWGA{i} ro, [4] RFPWGA{i}
0xFFFFA18A ICP9 16-bit
0xFFFFA18A ICP9L
  [7] MKP9, [6] TBP9, [2] P2P9, [1] P1P9, [0] P0P9
0xFFFFA18B ICP9H
  [7] CTP9 ro, [4] RFP9
{0xFFFFA172+2i} ICP{i} 16-bit (i=13..15)
{0xFFFFA172+2i} ICP{i}L (i=13..15)
  [7] MKP{i}, [6] TBP{i}, [2] P2P{i}, [1] P1P{i}, [0] P0P{i}
{0xFFFFA173+2i} ICP{i}H (i=13..15)
  [7] CTP{i} ro, [4] RFP{i}
0xFFFFA192 ICRTCA01S 16-bit
0xFFFFA192 ICRTCA01SL
  [7] MKRTCA01S, [6] TBRTCA01S, [2] P2RTCA01S, [1] P1RTCA01S, [0] P0RTCA01S
0xFFFFA193 ICRTCA01SH
  [7] CTRTCA01S ro, [4] RFRTCA01S
0xFFFFA194 ICRTCA0AL 16-bit
0xFFFFA194 ICRTCA0ALL
  [7] MKRTCA0AL, [6] TBRTCA0AL, [2] P2RTCA0AL, [1] P1RTCA0AL, [0] P0RTCA0AL
0xFFFFA195 ICRTCA0ALH
  [7] CTRTCA0AL ro, [4] RFRTCA0AL
0xFFFFA196 ICRTCA0R 16-bit
0xFFFFA196 ICRTCA0RL
  [7] MKRTCA0R, [6] TBRTCA0R, [2] P2RTCA0R, [1] P1RTCA0R, [0] P0RTCA0R
0xFFFFA197 ICRTCA0RH
  [7] CTRTCA0R ro, [4] RFRTCA0R
0xFFFFA198 ICADCA1ERR 16-bit
0xFFFFA198 ICADCA1ERRL
  [7] MKADCA1ERR, [6] TBADCA1ERR, [2] P2ADCA1ERR, [1] P1ADCA1ERR, [0] P0ADCA1ERR
0xFFFFA199 ICADCA1ERRH
  [7] CTADCA1ERR ro, [4] RFADCA1ERR
{0xFFFFA19A+2i} ICADCA1I{i} 16-bit (i=0..2)
{0xFFFFA19A+2i} ICADCA1I{i}L (i=0..2)
  [7] MKADCA1I{i}, [6] TBADCA1I{i}, [2] P2ADCA1I{i}, [1] P1ADCA1I{i}, [0] P0ADCA1I{i}
{0xFFFFA19B+2i} ICADCA1I{i}H (i=0..2)
  [7] CTADCA1I{i} ro, [4] RFADCA1I{i}
0xFFFFA1A2 ICRCAN2ERR 16-bit
0xFFFFA1A2 ICRCAN2ERRL
  [7] MKRCAN2ERR, [6] TBRCAN2ERR, [2] P2RCAN2ERR, [1] P1RCAN2ERR, [0] P0RCAN2ERR
0xFFFFA1A3 ICRCAN2ERRH
  [7] CTRCAN2ERR ro, [4] RFRCAN2ERR
0xFFFFA1A4 ICRCAN2REC 16-bit
0xFFFFA1A4 ICRCAN2RECL
  [7] MKRCAN2REC, [6] TBRCAN2REC, [2] P2RCAN2REC, [1] P1RCAN2REC, [0] P0RCAN2REC
0xFFFFA1A5 ICRCAN2RECH
  [7] CTRCAN2REC ro, [4] RFRCAN2REC
0xFFFFA1A6 ICRCAN2TRX 16-bit
0xFFFFA1A6 ICRCAN2TRXL
  [7] MKRCAN2TRX, [6] TBRCAN2TRX, [2] P2RCAN2TRX, [1] P1RCAN2TRX, [0] P0RCAN2TRX
0xFFFFA1A7 ICRCAN2TRXH
  [7] CTRCAN2TRX ro, [4] RFRCAN2TRX
0xFFFFA1A8 ICRCAN3ERR 16-bit
0xFFFFA1A8 ICRCAN3ERRL
  [7] MKRCAN3ERR, [6] TBRCAN3ERR, [2] P2RCAN3ERR, [1] P1RCAN3ERR, [0] P0RCAN3ERR
0xFFFFA1A9 ICRCAN3ERRH
  [7] CTRCAN3ERR ro, [4] RFRCAN3ERR
0xFFFFA1AA ICRCAN3REC 16-bit
0xFFFFA1AA ICRCAN3RECL
  [7] MKRCAN3REC, [6] TBRCAN3REC, [2] P2RCAN3REC, [1] P1RCAN3REC, [0] P0RCAN3REC
0xFFFFA1AB ICRCAN3RECH
  [7] CTRCAN3REC ro, [4] RFRCAN3REC
0xFFFFA1AC ICRCAN3TRX 16-bit
0xFFFFA1AC ICRCAN3TRXL
  [7] MKRCAN3TRX, [6] TBRCAN3TRX, [2] P2RCAN3TRX, [1] P1RCAN3TRX, [0] P0RCAN3TRX
0xFFFFA1AD ICRCAN3TRXH
  [7] CTRCAN3TRX ro, [4] RFRCAN3TRX
0xFFFFA1AE ICCSIG1IC 16-bit
0xFFFFA1AE ICCSIG1ICL
  [7] MKCSIG1IC, [6] TBCSIG1IC, [2] P2CSIG1IC, [1] P1CSIG1IC, [0] P0CSIG1IC
0xFFFFA1AF ICCSIG1ICH
  [7] CTCSIG1IC ro, [4] RFCSIG1IC
0xFFFFA1B0 ICCSIG1IR 16-bit
0xFFFFA1B0 ICCSIG1IRL
  [7] MKCSIG1IR, [6] TBCSIG1IR, [2] P2CSIG1IR, [1] P1CSIG1IR, [0] P0CSIG1IR
0xFFFFA1B1 ICCSIG1IRH
  [7] CTCSIG1IR ro, [4] RFCSIG1IR
0xFFFFA1B2 ICCSIG1IRE 16-bit
0xFFFFA1B2 ICCSIG1IREL
  [7] MKCSIG1IRE, [6] TBCSIG1IRE, [2] P2CSIG1IRE, [1] P1CSIG1IRE, [0] P0CSIG1IRE
0xFFFFA1B3 ICCSIG1IREH
  [7] CTCSIG1IRE ro, [4] RFCSIG1IRE
0xFFFFA1B4 ICRLIN24 16-bit
0xFFFFA1B4 ICRLIN24L
  [7] MKRLIN24, [6] TBRLIN24, [2] P2RLIN24, [1] P1RLIN24, [0] P0RLIN24
0xFFFFA1B5 ICRLIN24H
  [7] CTRLIN24 ro, [4] RFRLIN24
0xFFFFA1B6 ICRLIN25 16-bit
0xFFFFA1B6 ICRLIN25L
  [7] MKRLIN25, [6] TBRLIN25, [2] P2RLIN25, [1] P1RLIN25, [0] P0RLIN25
0xFFFFA1B7 ICRLIN25H
  [7] CTRLIN25 ro, [4] RFRLIN25
{0xFFFFA0B0+8i} ICRLIN{i} 16-bit (i=33..35)
{0xFFFFA0B0+8i} ICRLIN{i}L (i=33..35)
  [7] MKRLIN{i}, [6] TBRLIN{i}, [2] P2RLIN{i}, [1] P1RLIN{i}, [0] P0RLIN{i}
{0xFFFFA0B1+8i} ICRLIN{i}H (i=33..35)
  [7] CTRLIN{i} ro, [4] RFRLIN{i}
{0xFFFFA1BA+2i} ICRLIN33UR{i} 16-bit (i=0..2)
{0xFFFFA1BA+2i} ICRLIN33UR{i}L (i=0..2)
  [7] MKRLIN33UR{i}, [6] TBRLIN33UR{i}, [2] P2RLIN33UR{i}, [1] P1RLIN33UR{i}, [0] P0RLIN33UR{i}
{0xFFFFA1BB+2i} ICRLIN33UR{i}H (i=0..2)
  [7] CTRLIN33UR{i} ro, [4] RFRLIN33UR{i}
{0xFFFFA1C2+2i} ICRLIN34UR{i} 16-bit (i=0..2)
{0xFFFFA1C2+2i} ICRLIN34UR{i}L (i=0..2)
  [7] MKRLIN34UR{i}, [6] TBRLIN34UR{i}, [2] P2RLIN34UR{i}, [1] P1RLIN34UR{i}, [0] P0RLIN34UR{i}
{0xFFFFA1C3+2i} ICRLIN34UR{i}H (i=0..2)
  [7] CTRLIN34UR{i} ro, [4] RFRLIN34UR{i}
{0xFFFFA1CA+2i} ICRLIN35UR{i} 16-bit (i=0..2)
{0xFFFFA1CA+2i} ICRLIN35UR{i}L (i=0..2)
  [7] MKRLIN35UR{i}, [6] TBRLIN35UR{i}, [2] P2RLIN35UR{i}, [1] P1RLIN35UR{i}, [0] P0RLIN35UR{i}
{0xFFFFA1CB+2i} ICRLIN35UR{i}H (i=0..2)
  [7] CTRLIN35UR{i} ro, [4] RFRLIN35UR{i}
{0xFFFFA170+2i} ICPWGA{i} 16-bit (i=48..63)
{0xFFFFA170+2i} ICPWGA{i}L (i=48..63)
  fields as ICPWGA0L
{0xFFFFA171+2i} ICPWGA{i}H (i=48..63)
  [7] CTPWGA{i} ro, [4] RFPWGA{i}
{0xFFFFA1F0+2i} ICTAUB1I{i} 16-bit (i=0..15)
{0xFFFFA1F0+2i} ICTAUB1I{i}L (i=0..15)
  [7] MKTAUB1I{i}, [6] TBTAUB1I{i}, [2] P2TAUB1I{i}, [1] P1TAUB1I{i}, [0] P0TAUB1I{i}
{0xFFFFA1F1+2i} ICTAUB1I{i}H (i=0..15)
  [7] CTTAUB1I{i} ro, [4] RFTAUB1I{i}
0xFFFFA210 ICRCAN4ERR 16-bit
0xFFFFA210 ICRCAN4ERRL
  [7] MKRCAN4ERR, [6] TBRCAN4ERR, [2] P2RCAN4ERR, [1] P1RCAN4ERR, [0] P0RCAN4ERR
0xFFFFA211 ICRCAN4ERRH
  [7] CTRCAN4ERR ro, [4] RFRCAN4ERR
0xFFFFA212 ICRCAN4REC 16-bit
0xFFFFA212 ICRCAN4RECL
  [7] MKRCAN4REC, [6] TBRCAN4REC, [2] P2RCAN4REC, [1] P1RCAN4REC, [0] P0RCAN4REC
0xFFFFA213 ICRCAN4RECH
  [7] CTRCAN4REC ro, [4] RFRCAN4REC
0xFFFFA214 ICRCAN4TRX 16-bit
0xFFFFA214 ICRCAN4TRXL
  [7] MKRCAN4TRX, [6] TBRCAN4TRX, [2] P2RCAN4TRX, [1] P1RCAN4TRX, [0] P0RCAN4TRX
0xFFFFA215 ICRCAN4TRXH
  [7] CTRCAN4TRX ro, [4] RFRCAN4TRX
0xFFFFA216 ICRLIN26 16-bit
0xFFFFA216 ICRLIN26L
  [7] MKRLIN26, [6] TBRLIN26, [2] P2RLIN26, [1] P1RLIN26, [0] P0RLIN26
0xFFFFA217 ICRLIN26H
  [7] CTRLIN26 ro, [4] RFRLIN26
0xFFFFA218 ICRLIN27 16-bit
0xFFFFA218 ICRLIN27L
  [7] MKRLIN27, [6] TBRLIN27, [2] P2RLIN27, [1] P1RLIN27, [0] P0RLIN27
0xFFFFA219 ICRLIN27H
  [7] CTRLIN27 ro, [4] RFRLIN27
{0xFFFFA19A+2i} ICPWGA{i} 16-bit (i=64..71)
{0xFFFFA19A+2i} ICPWGA{i}L (i=64..71)
  fields as ICPWGA0L
{0xFFFFA19B+2i} ICPWGA{i}H (i=64..71)
  [7] CTPWGA{i} ro, [4] RFPWGA{i}
0xFFFFA22A ICRLIN28 16-bit
0xFFFFA22A ICRLIN28L
  [7] MKRLIN28, [6] TBRLIN28, [2] P2RLIN28, [1] P1RLIN28, [0] P0RLIN28
0xFFFFA22B ICRLIN28H
  [7] CTRLIN28 ro, [4] RFRLIN28
0xFFFFA22C ICRLIN29 16-bit
0xFFFFA22C ICRLIN29L
  [7] MKRLIN29, [6] TBRLIN29, [2] P2RLIN29, [1] P1RLIN29, [0] P0RLIN29
0xFFFFA22D ICRLIN29H
  [7] CTRLIN29 ro, [4] RFRLIN29
0xFFFFA22E ICRCAN5ERR 16-bit
0xFFFFA22E ICRCAN5ERRL
  [7] MKRCAN5ERR, [6] TBRCAN5ERR, [2] P2RCAN5ERR, [1] P1RCAN5ERR, [0] P0RCAN5ERR
0xFFFFA22F ICRCAN5ERRH
  [7] CTRCAN5ERR ro, [4] RFRCAN5ERR
0xFFFFA230 ICRCAN5REC 16-bit
0xFFFFA230 ICRCAN5RECL
  [7] MKRCAN5REC, [6] TBRCAN5REC, [2] P2RCAN5REC, [1] P1RCAN5REC, [0] P0RCAN5REC
0xFFFFA231 ICRCAN5RECH
  [7] CTRCAN5REC ro, [4] RFRCAN5REC
0xFFFFA232 ICRCAN5TRX 16-bit
0xFFFFA232 ICRCAN5TRXL
  [7] MKRCAN5TRX, [6] TBRCAN5TRX, [2] P2RCAN5TRX, [1] P1RCAN5TRX, [0] P0RCAN5TRX
0xFFFFA233 ICRCAN5TRXH
  [7] CTRCAN5TRX ro, [4] RFRCAN5TRX
{0xFFFFA400+4i} IMR{i} 32-bit (i=1..8)
{0xFFFFA400+4i} IMR{i}L 16-bit (i=1..8)
0xFFFFA404 IMR1LL
  [n-32] IMR1EIMK{n} (n=32..39)
0xFFFFA405 IMR1LH
  [n-40] IMR1EIMK{n} (n=40..47)
{0xFFFFA402+4i} IMR{i}H 16-bit (i=1..8)
0xFFFFA406 IMR1HL
  [n-48] IMR1EIMK{n} (n=49..55)
0xFFFFA407 IMR1HH
  [n-56] IMR1EIMK{n} (n=56..63)
0xFFFFA408 IMR2LL
  [n-64] IMR2EIMK{n} (n=64..71)
0xFFFFA409 IMR2LH
  [n-72] IMR2EIMK{n} (n=72..79)
0xFFFFA40A IMR2HL
  [n-80] IMR2EIMK{n} (n=80..87)
0xFFFFA40B IMR2HH
  [n-88] IMR2EIMK{n} (n=88..95)
0xFFFFA40C IMR3LL
  [7] IMR3EIMK103, [6] IMR3EIMK102
0xFFFFA40D IMR3LH
  [n-104] IMR3EIMK{n} (n=104..111)
0xFFFFA40E IMR3HL
  [n-112] IMR3EIMK{n} (n=112..119)
0xFFFFA40F IMR3HH
  [n-120] IMR3EIMK{n} (n=120..127)
0xFFFFA410 IMR4LL
  [7] IMR4EIMK135, [6] IMR4EIMK134
0xFFFFA411 IMR4LH
  [n-136] IMR4EIMK{n} (n=136..143)
0xFFFFA412 IMR4HL
  [n-144] IMR4EIMK{n} (n=144..151)
0xFFFFA413 IMR4HH
  [n-152] IMR4EIMK{n} (n=152..159)
0xFFFFA414 IMR5LL
  [n-160] IMR5EIMK{n} (n=160..163)
0xFFFFA416 IMR5HL
  [n-176] IMR5EIMK{n} (n=176..183)
0xFFFFA417 IMR5HH
  [n-184] IMR5EIMK{n} (n=184..191)
0xFFFFA418 IMR6LL
  [n-192] IMR6EIMK{n} (n=192..199)
0xFFFFA419 IMR6LH
  [n-200] IMR6EIMK{n} (n=200..207)
0xFFFFA41A IMR6HL
  [n-208] IMR6EIMK{n} (n=209..215)
0xFFFFA41B IMR6HH
  [n-216] IMR6EIMK{n} (n=216..223)
0xFFFFA41C IMR7LL
  [n-224] IMR7EIMK{n} (n=224..231)
0xFFFFA41D IMR7LH
  [n-232] IMR7EIMK{n} (n=232..239)
0xFFFFA41E IMR7HL
  [n-240] IMR7EIMK{n} (n=240..247)
0xFFFFA41F IMR7HH
  [n-248] IMR7EIMK{n} (n=248..255)
0xFFFFA420 IMR8LL
  [n-256] IMR8EIMK{n} (n=256..263)
0xFFFFA421 IMR8LH
  [n-264] IMR8EIMK{n} (n=264..271)
0xFFFFA422 IMR8HL
  [n-272] IMR8EIMK{n} (n=272..279)
0xFFFFA423 IMR8HH
  [1] IMR8EIMK281, [0] IMR8EIMK280
